# ESP32C6_RADIO register map
File version: 0.1.0
Registers are 32-bit, read-write, no defined reset value unless marked. A register's access mark holds for its fields unless they carry their own. Offsets are from the block's base; [hi:lo] are bit positions.

## MODEM_LPCON — Modem LP reset Documented register; the behaviour the HAL does not document is under MODEM_SYSCON_MODEM_RST_CONF_REG.
Base 0x600AF000
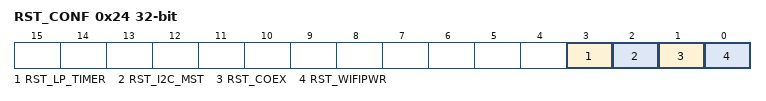
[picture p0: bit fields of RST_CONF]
0x24 RST_CONF — Modem LP resets, pulsed at boot against stale modem state The library writes 0xf, then 0, at `PRE_KERNEL_1` through `modem_lpcon_ll_reset_all()`, with MODEM_SYSCON_MODEM_RST_CONF_REG (see there for why). Evidence: *measured* bench 2026-10-09 (symptoms under "Stale modem state"); *working* `lib/esp_sdr/src/esp_sdr.c:29-48`; `modules/hal/espressif/components/hal/esp32c6/include/hal/modem_lpcon_ll.h:266-270`, `modules/hal/espressif/components/esp_system/port/soc/esp32c6/system_internal.c:45-46`
  [3] RST_LP_TIMER wo — Set, then cleared, at boot (0xf, then 0).
  [2] RST_I2C_MST wo — Set, then cleared, at boot (0xf, then 0).
  [1] RST_COEX wo — Set, then cleared, at boot (0xf, then 0).
  [0] RST_WIFIPWR wo — Set, then cleared, at boot (0xf, then 0).

## IO_MUX — Modem diagnostic lines
Base 0x60090000
0xBC MODEM_DIAG_EN — Routes modem diagnostic lines into the GPIO matrix
  [31:0] MODEM_DIAG_EN — Bit i routes modem_diag[i] into the GPIO matrix. After writing their selectors (DUMP_DIAG_SEL0_REG, DUMP_DIAG_SEL1_REG), `gpio_diag_init_ble()` enables 0xffff0000 here and `coex_hw_debug_matrix_config()` 0x0000000f. A lead for a continuous receive below 80 MS/s (see "Dump and DAC engine"). Evidence: `modules/hal/espressif/components/soc/esp32c6/register/soc/io_mux_reg.h:325-336`; *decompile* C6 `libble_app.a` `gpio_diag.c.o`, `libcoexist.a` `coexist_hw.o`

## BTBB — BTBB page (0x600a2000)
Base 0x600A2000
0xB4 RB4 — Dump gate in bit 0
  [0] DUMP_GATE — Cleared before every capture, as the stock sequence. The C6 `adctrig()` clears it in every mode but 8, the BLE baseband dump, which sets it (see "Receive rate" under "Dump and DAC engine"); upstream's ESP32-H2 notes call it the trigger source. Evidence: *working* `lib/esp_sdr/src/esp_sdr_rx.c:261`; *decompile* C6 `librftest.a` `mac_common.o`; *upstream* `modules/lib/esp-sdr/main/targets/esp32c6/chip.h:40`, `modules/lib/esp-sdr/docs/esp32h2.md:20`
0x8A0 R8A0 — Unknown; bits 31:30 written by the BT branch of `force_txon_mode()`
  [31:30] B31_30 — Only with the BT flag (its second argument), `force_txon_mode(on, bt, idx)` stops the hardware frequency engine (FE_HW_FREQ_STOP, 0x600a00c0 bit 26), writes 0x600af4b4 bit 0, FE_BT_FORCE (0x600a0910 bits 13:12) and these bits (all ones with `on`, 0 without), and restarts the engine if it ran before (see "Front end").

## WIFIMAC — Wi-Fi MAC page (0x600a4000)
Base 0x600A4000
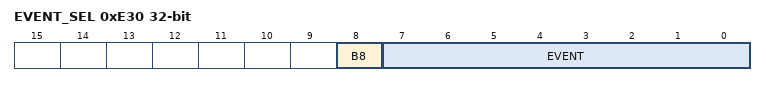
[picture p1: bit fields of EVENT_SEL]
0xE30 EVENT_SEL — Wi-Fi MAC event selector, used by the dump's `adctrig()` mode 7 Evidence: *decompile* C6 `librftest.a` `mac_common.o`
  [8] B8 — Set by `adctrig()` mode 7.
  [7:0] EVENT — The event, written by `adctrig()` mode 7 (DUMP_SRC 5; see "Receive rate" under "Dump and DAC engine").

## AGC — AGC force
Base 0x600A7000
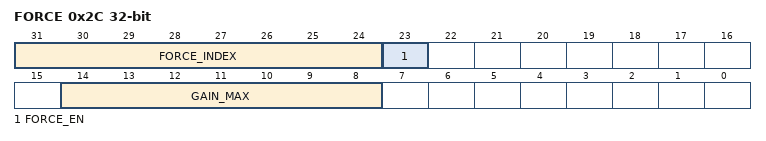
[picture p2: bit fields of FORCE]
0x2C FORCE — Forced receive gain index, force bit and largest calibrated index Same layout as the S3's 0x6001c02c; upstream calls the register AGCPWR_CTRL7. On the C6, `force_rx_gain(force, index, 0)` writes only this register. A new forced index alone can leave stale receive state, so a gain change reruns the front-end setup. Evidence: *working* `lib/esp_sdr/src/esp_sdr_priv.h:111-113`; *decompile* C6 `librftest.a` `phy_test.o` (`force_rx_gain`); *upstream* `modules/lib/esp-sdr/main/common/burst_gain.h:11-12, 36` Evidence: `lib/esp_sdr/src/esp_sdr_rx.c:164-166` (front-end rerun)
  [31:24] FORCE_INDEX — Forced receive gain index.
  [23] FORCE_EN — Force: 1 holds the index, 0 hands the gain to the AGC.
  [14:8] GAIN_MAX — Largest calibrated gain index, as on the S3: below 80 (library cap 79). Larger reads point at uncalibrated slots; the library treats them as 0.
0x30 R30 — Unknown; bit 5 cleared in the 802.11p clock mode
  [5] B5 — `phy_11p_set(1, m)` writes MODEM_SYSCON_WIFI_BB_CFG_REG bits 4:2 and clears this bit (the 802.11p clock mode, a lead under "Dump and DAC engine"). Evidence: *decompile* C6 `libphy.a` `phy_feature.o`
0xB8 RB8 — Unknown; bits 2:0 written by `set_dump_mode()`
  [2:0] B2_0 — `set_dump_mode(x)` clears FE_R958_REG (0x600a0958) bits 1:0 and writes 1 here when x is 0, else 0. Evidence: C6 `librftest.a` `phy_test.o`
0xDC RDC — Unknown; bit 16 cleared by `force_txon()`
  [16] B16 — `force_txon(on)` clears it and sets FE_RX_FORCE (0x600a0910 bits 9:8) to 2, then FE_TX_FORCE (bits 11:10) to 3; off goes in reverse. `force_txon_mode()` calls `force_txon(0)`, then `force_txon(on)` (see "Front end").
